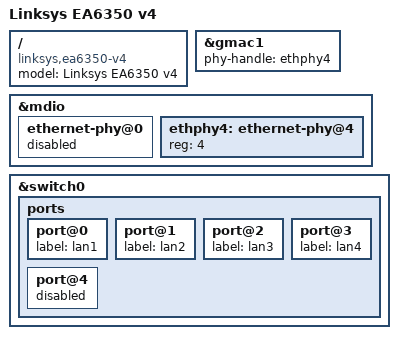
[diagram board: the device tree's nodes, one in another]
// SPDX-License-Identifier: GPL-2.0-or-later OR MIT

#include "mt7621_linksys_ea7xxx.dtsi"

/ {
	compatible = "linksys,ea6350-v4", "mediatek,mt7621-soc";
	model = "Linksys EA6350 v4";
};

&gmac1 {
	phy-handle = <&ethphy4>;
};

&mdio {
	ethernet-phy@0 {
		status = "disabled";
	};

	ethphy4: ethernet-phy@4 {
		reg = <4>;
	};
};

&switch0 {
	ports {
		port@0 {
			status = "okay";
			label = "lan1";
		};

		port@1 {
			status = "okay";
			label = "lan2";
		};

		port@2 {
			status = "okay";
			label = "lan3";
		};

		port@3 {
			status = "okay";
			label = "lan4";
		};

		port@4 {
			status = "disabled";
		};
	};
};
